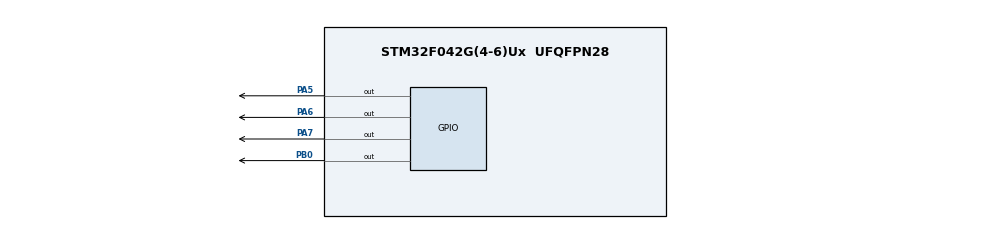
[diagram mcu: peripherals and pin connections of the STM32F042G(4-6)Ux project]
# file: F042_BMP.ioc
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Mcu.Family=STM32F0
Mcu.Name=STM32F042G(4-6)Ux
Mcu.Package=UFQFPN28
PA13.Mode=Serial_Wire
PA13.Signal=SYS_SWDIO
PA14.Mode=Serial_Wire
PA14.Signal=SYS_SWCLK
PA5.Signal=GPIO_Output
PA6.Signal=GPIO_Output
PA7.Signal=GPIO_Output
PB0.Signal=GPIO_Output
ProjectManager.HeapSize=0x200
ProjectManager.StackSize=0x400
ProjectManager.TargetToolchain=MDK-ARM V5.32
RCC.AHBFreq_Value=48000000
RCC.APB1Freq_Value=48000000
RCC.APB1TimFreq_Value=48000000
RCC.HCLKFreq_Value=48000000
RCC.SYSCLKFreq_VALUE=48000000
RCC.SYSCLKSource=RCC_SYSCLKSOURCE_HSI48
board=custom

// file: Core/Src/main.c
/* USER CODE BEGIN Header */
/**
  ******************************************************************************
  * @file           : main.c
  * @brief          : Main program body
  ******************************************************************************
  * @attention
  *
  * Copyright (c) 2025 STMicroelectronics.
  * All rights reserved.
  *
  * This software is licensed under terms that can be found in the LICENSE file
  * in the root directory of this software component.
  * If no LICENSE file comes with this software, it is provided AS-IS.
  *
  ******************************************************************************
  */
/* USER CODE END Header */
#include "main.h"
#include "gpio.h"

void SystemClock_Config(void);

int main(void)
{

  /* MCU Configuration--------------------------------------------------------*/

  /* Reset of all peripherals, Initializes the Flash interface and the Systick. */
  LL_APB1_GRP2_EnableClock(LL_APB1_GRP2_PERIPH_SYSCFG);
  LL_APB1_GRP1_EnableClock(LL_APB1_GRP1_PERIPH_PWR);

  /* SysTick_IRQn interrupt configuration */
  NVIC_SetPriority(SysTick_IRQn, 3);

  /* Configure the system clock */
  SystemClock_Config();

  /* Initialize all configured peripherals */
  MX_GPIO_Init();
  /* USER CODE BEGIN 2 */
	LL_GPIO_SetOutputPin(GPIOA,LL_GPIO_PIN_5);
	LL_GPIO_SetOutputPin(GPIOA,LL_GPIO_PIN_6);
	LL_GPIO_SetOutputPin(GPIOA,LL_GPIO_PIN_7);
	LL_GPIO_SetOutputPin(GPIOB,LL_GPIO_PIN_0);

  /* USER CODE END 2 */

  /* Infinite loop */
  while (1)
  {

  }
}

void SystemClock_Config(void)
{
  LL_FLASH_SetLatency(LL_FLASH_LATENCY_1);
  while(LL_FLASH_GetLatency() != LL_FLASH_LATENCY_1)
  {
  }
  LL_RCC_HSI48_Enable();

   /* Wait till HSI48 is ready */
  while(LL_RCC_HSI48_IsReady() != 1)
  {

  }
  LL_RCC_SetAHBPrescaler(LL_RCC_SYSCLK_DIV_1);
  LL_RCC_SetAPB1Prescaler(LL_RCC_APB1_DIV_1);
  LL_RCC_SetSysClkSource(LL_RCC_SYS_CLKSOURCE_HSI48);

   /* Wait till System clock is ready */
  while(LL_RCC_GetSysClkSource() != LL_RCC_SYS_CLKSOURCE_STATUS_HSI48)
  {

  }
  LL_Init1msTick(48000000);
  LL_SetSystemCoreClock(48000000);
}

void Error_Handler(void)
{
  __disable_irq();
  while (1)
  {
  }
}
